VERSION ""

NS_ :

BS_:

BU_:

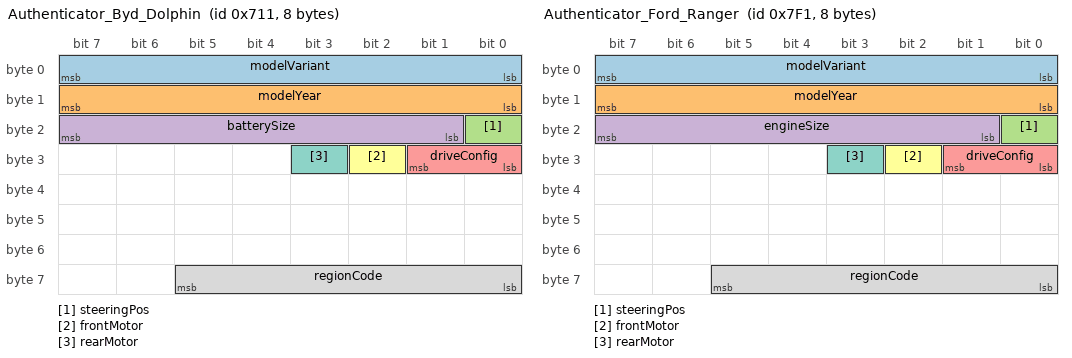
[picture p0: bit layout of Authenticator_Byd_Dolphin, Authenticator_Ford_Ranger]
BO_ 1809 Authenticator_Byd_Dolphin: 8 Vector__XXX
 SG_ modelVariant : 0|8@1+ (1,0) [0|255] "" Vector__XXX
 SG_ modelYear : 8|8@1+ (1,2020) [2020|2275] "year" Vector__XXX
 SG_ steeringPos : 16|1@1+ (1,0) [0|1] "" Vector__XXX
 SG_ batterySize : 17|7@1+ (1,0) [0|127] "kWh" Vector__XXX
 SG_ driveConfig : 24|2@1+ (1,0) [0|3] "" Vector__XXX
 SG_ frontMotor : 26|1@1+ (1,0) [0|1] "" Vector__XXX
 SG_ rearMotor : 27|1@1+ (1,0) [0|1] "" Vector__XXX
 SG_ regionCode : 56|6@1+ (1,0) [0|63] "" Vector__XXX

BO_ 2033 Authenticator_Ford_Ranger: 8 Vector__XXX
 SG_ modelVariant : 0|8@1+ (1,0) [0|255] "" Vector__XXX
 SG_ modelYear : 8|8@1+ (1,2020) [2020|2275] "year" Vector__XXX
 SG_ steeringPos : 16|1@1+ (1,0) [0|1] "" Vector__XXX
 SG_ engineSize : 17|7@1+ (0.1,0) [0|12.7] "L" Vector__XXX
 SG_ driveConfig : 24|2@1+ (1,0) [0|3] "" Vector__XXX
 SG_ frontMotor : 26|1@1+ (1,0) [0|1] "" Vector__XXX
 SG_ rearMotor : 27|1@1+ (1,0) [0|1] "" Vector__XXX
 SG_ regionCode : 56|6@1+ (1,0) [0|63] "" Vector__XXX

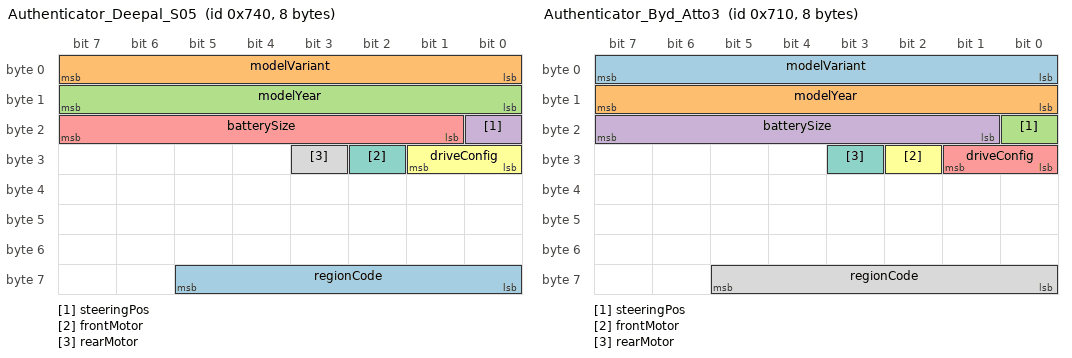
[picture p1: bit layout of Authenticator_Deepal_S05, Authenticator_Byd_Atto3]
BO_ 1856 Authenticator_Deepal_S05: 8 Vector__XXX
 SG_ regionCode : 56|6@1+ (1,0) [0|63] "" Vector__XXX
 SG_ modelVariant : 0|8@1+ (1,0) [0|255] "" Vector__XXX
 SG_ modelYear : 8|8@1+ (1,2020) [2020|2275] "year" Vector__XXX
 SG_ steeringPos : 16|1@1+ (1,0) [0|1] "" Vector__XXX
 SG_ batterySize : 17|7@1+ (1,0) [0|127] "kWh" Vector__XXX
 SG_ driveConfig : 24|2@1+ (1,0) [0|3] "" Vector__XXX
 SG_ frontMotor : 26|1@1+ (1,0) [0|1] "" Vector__XXX
 SG_ rearMotor : 27|1@1+ (1,0) [0|1] "" Vector__XXX

BO_ 1808 Authenticator_Byd_Atto3: 8 Vector__XXX
 SG_ modelVariant : 0|8@1+ (1,0) [0|255] "" Vector__XXX
 SG_ modelYear : 8|8@1+ (1,2020) [2020|2275] "year" Vector__XXX
 SG_ steeringPos : 16|1@1+ (1,0) [0|1] "" Vector__XXX
 SG_ batterySize : 17|7@1+ (1,0) [0|127] "kWh" Vector__XXX
 SG_ driveConfig : 24|2@1+ (1,0) [0|3] "" Vector__XXX
 SG_ frontMotor : 26|1@1+ (1,0) [0|1] "" Vector__XXX
 SG_ rearMotor : 27|1@1+ (1,0) [0|1] "" Vector__XXX
 SG_ regionCode : 56|6@1+ (1,0) [0|63] "" Vector__XXX

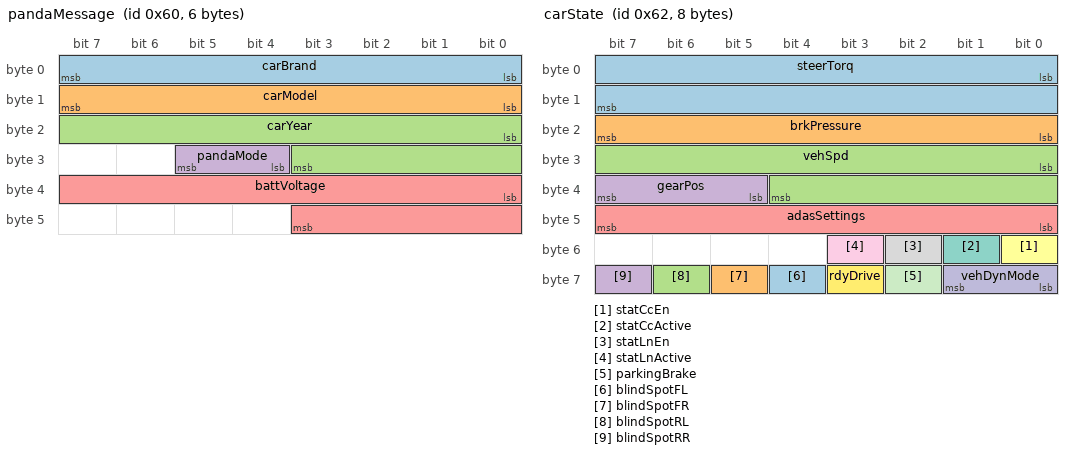
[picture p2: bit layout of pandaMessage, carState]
BO_ 96 pandaMessage: 6 Vector__XXX
 SG_ carBrand : 0|8@1+ (1,0) [0|255] "" Vector__XXX
 SG_ carModel : 8|8@1+ (1,0) [0|255] "" Vector__XXX
 SG_ carYear : 16|12@1+ (1,0) [0|4095] "" Vector__XXX
 SG_ pandaMode : 28|2@1+ (1,0) [0|3] "" Vector__XXX
 SG_ battVoltage : 32|12@1+ (0.01,0) [0|40.95] "V" Vector__XXX

BO_ 97 userCommand: 8 Vector__XXX
 SG_ brkPedal : 0|8@1+ (0.4,0) [0|102] "%" Vector__XXX
 SG_ accPedal : 8|8@1+ (0.4,0) [0|102] "%" Vector__XXX
 SG_ steerAngle : 16|16@1+ (0.1,0) [-780|780] "deg" Vector__XXX
 SG_ yawRate : 32|14@1+ (0.01,-81.91) [-81.91|81.91] "deg/s" Vector__XXX
 SG_ btnCcEn : 46|1@1+ (1,0) [0|1] "" Vector__XXX
 SG_ btnLaneEn : 47|1@1+ (1,0) [0|1] "" Vector__XXX
 SG_ btnGeneric : 48|1@1+ (1,0) [0|1] "" Vector__XXX
 SG_ btnCcSet : 49|1@1+ (1,0) [0|1] "" Vector__XXX
 SG_ btnCcCancel : 50|1@1+ (1,0) [0|1] "" Vector__XXX
 SG_ btnCcResume : 51|1@1+ (1,0) [0|1] "" Vector__XXX
 SG_ btnSpdUp : 52|1@1+ (1,0) [0|1] "" Vector__XXX
 SG_ btnSpdDn : 53|1@1+ (1,0) [0|1] "" Vector__XXX
 SG_ btnDistNr : 54|1@1+ (1,0) [0|1] "" Vector__XXX
 SG_ btnDistFar : 55|1@1+ (1,0) [0|1] "" Vector__XXX
 SG_ btnHazard : 56|1@1+ (1,0) [0|1] "" Vector__XXX
 SG_ btnBlinkL : 57|1@1+ (1,0) [0|1] "" Vector__XXX
 SG_ btnBlinkR : 58|1@1+ (1,0) [0|1] "" Vector__XXX
 SG_ actPedalPressed : 59|1@1+ (1,0) [0|1] "" Vector__XXX
 SG_ actBrakePressed : 60|1@1+ (1,0) [0|1] "" Vector__XXX
 SG_ actSteerPressed : 61|1@1+ (1,0) [0|1] "" Vector__XXX

BO_ 98 carState: 8 Vector__XXX
 SG_ steerTorq : 0|16@1+ (0.1,-3276.8) [-3276.8|3276.7] "Nm" Vector__XXX
 SG_ brkPressure : 16|8@1+ (0.1,0) [0|25.5] "bar" Vector__XXX
 SG_ vehSpd : 24|13@1+ (0.05625,0) [0|360] "km/h" Vector__XXX
 SG_ gearPos : 37|3@1+ (1,0) [0|7] "" Vector__XXX
 SG_ adasSettings : 40|8@1+ (1,0) [0|255] "" Vector__XXX
 SG_ statCcEn : 48|1@1+ (1,0) [0|1] "" Vector__XXX
 SG_ statCcActive : 49|1@1+ (1,0) [0|1] "" Vector__XXX
 SG_ statLnEn : 50|1@1+ (1,0) [0|1] "" Vector__XXX
 SG_ statLnActive : 51|1@1+ (1,0) [0|1] "" Vector__XXX
 SG_ vehDynMode : 56|2@1+ (1,0) [0|3] "" Vector__XXX
 SG_ parkingBrake : 58|1@1+ (1,0) [0|1] "" Vector__XXX
 SG_ rdyDrive : 59|1@1+ (1,0) [0|1] "" Vector__XXX
 SG_ blindSpotFL : 60|1@1+ (1,0) [0|1] "" Vector__XXX
 SG_ blindSpotFR : 61|1@1+ (1,0) [0|1] "" Vector__XXX
 SG_ blindSpotRL : 62|1@1+ (1,0) [0|1] "" Vector__XXX
 SG_ blindSpotRR : 63|1@1+ (1,0) [0|1] "" Vector__XXX

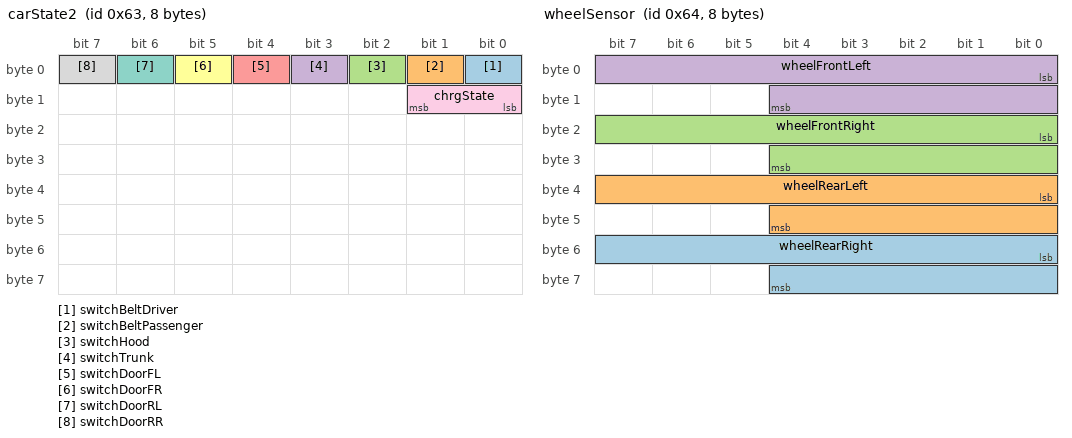
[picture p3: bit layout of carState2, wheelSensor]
BO_ 99 carState2: 8 Vector__XXX
 SG_ switchBeltDriver : 0|1@1+ (1,0) [0|1] "" Vector__XXX
 SG_ switchBeltPassenger : 1|1@1+ (1,0) [0|1] "" Vector__XXX
 SG_ switchHood : 2|1@1+ (1,0) [0|1] "" Vector__XXX
 SG_ switchTrunk : 3|1@1+ (1,0) [0|1] "" Vector__XXX
 SG_ switchDoorFL : 4|1@1+ (1,0) [0|1] "" Vector__XXX
 SG_ switchDoorFR : 5|1@1+ (1,0) [0|1] "" Vector__XXX
 SG_ switchDoorRL : 6|1@1+ (1,0) [0|1] "" Vector__XXX
 SG_ switchDoorRR : 7|1@1+ (1,0) [0|1] "" Vector__XXX
 SG_ chrgState : 8|2@1+ (1,0) [0|3] "" Vector__XXX

BO_ 100 wheelSensor: 8 Vector__XXX
 SG_ wheelRearRight : 48|13@1+ (0.05625,0) [0|360] "km/h" Vector__XXX
 SG_ wheelRearLeft : 32|13@1+ (0.05625,0) [0|360] "km/h" Vector__XXX
 SG_ wheelFrontRight : 16|13@1+ (0.05625,0) [0|360] "km/h" Vector__XXX
 SG_ wheelFrontLeft : 0|13@1+ (0.05625,0) [0|360] "km/h" Vector__XXX

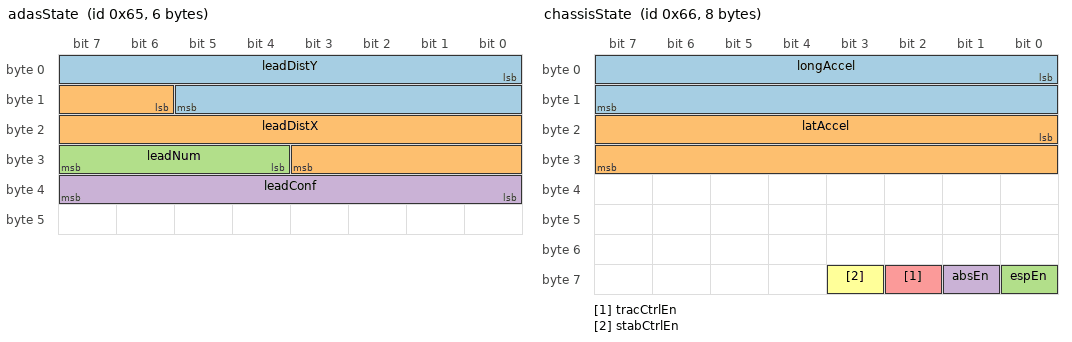
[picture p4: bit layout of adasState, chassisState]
BO_ 101 adasState: 6 Vector__XXX
 SG_ leadDistY : 0|14@1+ (0.04,0) [0|655.32] "m" Vector__XXX
 SG_ leadDistX : 14|14@1+ (0.04,0) [0|655.32] "m" Vector__XXX
 SG_ leadNum : 28|4@1+ (1,0) [0|3] "" Vector__XXX
 SG_ leadConf : 32|8@1+ (0.4,0) [0|102] "%" Vector__XXX

BO_ 102 chassisState: 8 Vector__XXX
 SG_ longAccel : 0|16@1+ (0.001,-32.768) [-32.768|32.767] "m/s2" Vector__XXX
 SG_ latAccel : 16|16@1+ (0.001,-32.768) [-32.768|32.767] "m/s2" Vector__XXX
 SG_ espEn : 56|1@1+ (1,0) [0|1] "" Vector__XXX
 SG_ absEn : 57|1@1+ (1,0) [0|1] "" Vector__XXX
 SG_ tracCtrlEn : 58|1@1+ (1,0) [0|1] "" Vector__XXX
 SG_ stabCtrlEn : 59|1@1+ (1,0) [0|1] "" Vector__XXX

BO_ 103 drivetrainState: 8 Vector__XXX
 SG_ gearRatio : 0|6@1+ (0.1,0) [0|6.3] "" Vector__XXX

BO_ 104 powertrainState: 8 Vector__XXX
 SG_ engRun : 0|1@1+ (1,0) [0|1] "" Vector__XXX
 SG_ pwrFault : 4|4@1+ (1,0) [0|15] "" Vector__XXX
 SG_ coolTemp : 8|8@1+ (1,-40) [-40|215] "C" Vector__XXX
 SG_ fuelLvl : 16|8@1+ (0.4,0) [0|102] "%" Vector__XXX
 SG_ battTemp : 24|8@1+ (1,-40) [-40|215] "C" Vector__XXX
 SG_ battLvl : 32|8@1+ (0.4,0) [0|102] "%" Vector__XXX
 SG_ engRPM : 48|16@1+ (0.25,0) [0|16383.75] "rpm" Vector__XXX
 SG_ engType : 62|2@1+ (1,0) [0|3] "" Vector__XXX

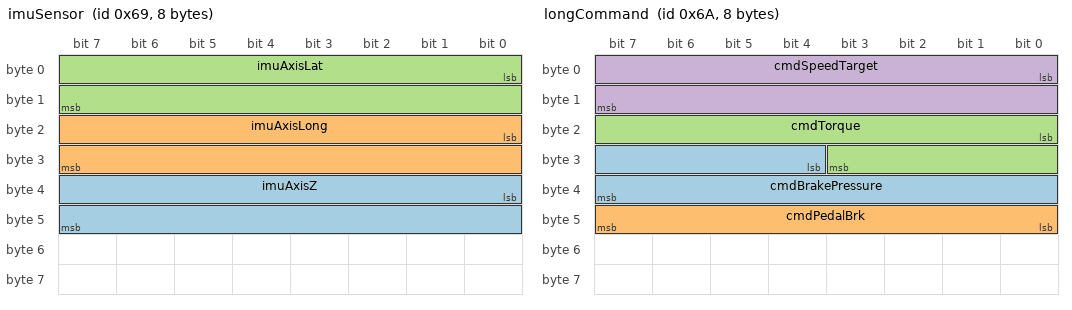
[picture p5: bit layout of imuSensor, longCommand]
BO_ 105 imuSensor: 8 Vector__XXX
 SG_ imuAxisZ : 32|16@1+ (0.001,-32.768) [-32.768|32.767] "m/s2" Vector__XXX
 SG_ imuAxisLong : 16|16@1+ (0.001,-32.768) [-32.768|32.767] "m/s2" Vector__XXX
 SG_ imuAxisLat : 0|16@1+ (0.001,-32.768) [-32.768|32.767] "m/s2" Vector__XXX

BO_ 106 longCommand: 8 Vector__XXX
 SG_ cmdBrakePressure : 28|12@1+ (0.015625,0) [0|1023.984375] "bar" Vector__XXX
 SG_ cmdPedalBrk : 40|8@1+ (0.4,0) [0|102] "%" Vector__XXX
 SG_ cmdTorque : 16|12@1+ (5,-5000) [-5000|15475] "NM" Vector__XXX
 SG_ cmdSpeedTarget : 0|16@1+ (0.01,0) [0|655.35] "km/h" Vector__XXX

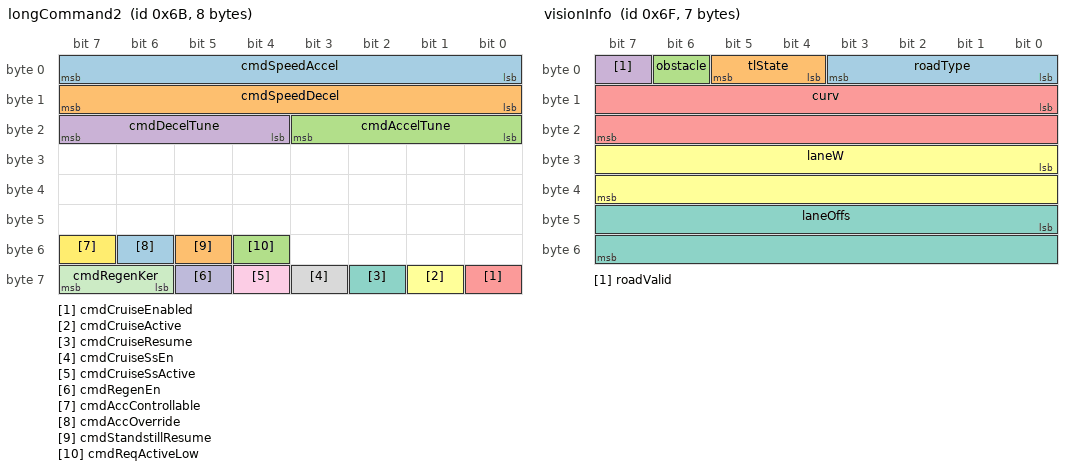
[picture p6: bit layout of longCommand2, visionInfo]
BO_ 107 longCommand2: 8 Vector__XXX
 SG_ cmdSpeedAccel : 0|8@1+ (0.05,-10) [-10|2.75] "m/s2" Vector__XXX
 SG_ cmdSpeedDecel : 8|8@1+ (0.05,-10) [-10|2.75] "m/s2" Vector__XXX
 SG_ cmdAccelTune : 16|4@1+ (1,0) [0|15] "" Vector__XXX
 SG_ cmdDecelTune : 20|4@1+ (1,0) [0|15] "" Vector__XXX
 SG_ cmdCruiseEnabled : 56|1@1+ (1,0) [0|1] "" Vector__XXX
 SG_ cmdCruiseActive : 57|1@1+ (1,0) [0|1] "" Vector__XXX
 SG_ cmdCruiseResume : 58|1@1+ (1,0) [0|1] "" Vector__XXX
 SG_ cmdCruiseSsEn : 59|1@1+ (1,0) [0|1] "" Vector__XXX
 SG_ cmdCruiseSsActive : 60|1@1+ (1,0) [0|1] "" Vector__XXX
 SG_ cmdRegenEn : 61|1@1+ (1,0) [0|1] "" Vector__XXX
 SG_ cmdRegenKer : 62|2@1+ (1,0) [0|1] "" Vector__XXX
 SG_ cmdAccControllable : 55|1@1+ (1,0) [0|1] "" Vector__XXX
 SG_ cmdAccOverride : 54|1@1+ (1,0) [0|1] "" Vector__XXX
 SG_ cmdStandstillResume : 53|1@1+ (1,0) [0|1] "" Vector__XXX
 SG_ cmdReqActiveLow : 52|1@1+ (1,0) [0|1] "" Vector__XXX

BO_ 108 latCommand: 8 Vector__XXX
 SG_ cmdSteerAngle : 0|16@1+ (0.1,-3276.8) [-3276.8|3276.7] "deg" Vector__XXX
 SG_ cmdSteerTorque : 16|16@1+ (0.01,-327.68) [-327.68|327.67] "Nm" Vector__XXX
 SG_ cmdSteerMode : 56|1@1+ (1,0) [0|1] "" Vector__XXX
 SG_ cmdSteerEnable : 57|1@1+ (1,0) [0|1] "" Vector__XXX
 SG_ cmdLaneActive : 58|1@1+ (1,0) [0|1] "" Vector__XXX
 SG_ cmdSteerAlert : 59|2@1+ (1,0) [0|3] "" Vector__XXX
 SG_ cmdSteerShake : 60|2@1+ (1,0) [0|3] "" Vector__XXX
 SG_ cmdLaneEnable : 62|1@1+ (1,0) [0|1] "" Vector__XXX
 SG_ cmdLaneAlert : 63|1@1+ (1,0) [0|1] "" Vector__XXX

BO_ 109 latCommand2: 8 Vector__XXX

BO_ 110 dispCommand: 8 Vector__XXX
 SG_ cmdDispCcEn : 0|1@1+ (1,0) [0|1] "" Vector__XXX
 SG_ cmdDispCcActive : 1|1@1+ (1,0) [0|1] "" Vector__XXX
 SG_ cmdDispLnEn : 2|1@1+ (1,0) [0|1] "" Vector__XXX
 SG_ cmdDispLnActive : 3|1@1+ (1,0) [0|1] "" Vector__XXX
 SG_ cmdDispSoundAlert : 4|1@1+ (1,0) [0|1] "" Vector__XXX
 SG_ cmdDispLeadC : 5|1@1+ (1,0) [0|1] "" Vector__XXX
 SG_ cmdDispLeadR : 6|1@1+ (1,0) [0|1] "" Vector__XXX
 SG_ cmdDispLeadL : 7|1@1+ (1,0) [0|1] "" Vector__XXX
 SG_ cmdDispDepartLeft : 8|1@1+ (1,0) [0|1] "" Vector__XXX
 SG_ cmdDispDepartRight : 9|1@1+ (1,0) [0|1] "" Vector__XXX
 SG_ cmdDispLane1 : 10|1@1+ (1,0) [0|1] "" Vector__XXX
 SG_ cmdDispLane2 : 11|1@1+ (1,0) [0|1] "" Vector__XXX
 SG_ cmdDispLane3 : 12|1@1+ (1,0) [0|1] "" Vector__XXX
 SG_ cmdDispLane4 : 13|1@1+ (1,0) [0|1] "" Vector__XXX
 SG_ cmdDispRoadEdgeLeft : 14|1@1+ (1,0) [0|1] "" Vector__XXX
 SG_ cmdDispRoadEdgeRight : 15|1@1+ (1,0) [0|1] "" Vector__XXX
 SG_ cmdDispFollowDistance : 16|2@1+ (1,0) [0|7] "" Vector__XXX
 SG_ cmdDispSpeed : 32|16@1+ (0.01,0) [0|655.35] "km/h" Vector__XXX
 SG_ cmdDispPassThrough : 48|16@1+ (1,0) [0|65535] "" Vector__XXX

BO_ 111 visionInfo: 7 Vector__XXX
 SG_ roadType : 0|4@1+ (1,0) [0|15] "" Vector__XXX
 SG_ tlState : 4|2@1+ (1,0) [0|3] "" Vector__XXX
 SG_ obstacle : 6|1@1+ (1,0) [0|1] "" Vector__XXX
 SG_ roadValid : 7|1@1+ (1,0) [0|1] "" Vector__XXX
 SG_ curv : 8|16@1+ (0.0001,-3.2768) [-3.2768|3.2767] "1/m" Vector__XXX
 SG_ laneW : 24|16@1+ (0.01,0) [0|655.35] "m" Vector__XXX
 SG_ laneOffs : 40|16@1+ (0.01,-327.68) [-327.68|327.67] "m" Vector__XXX

BA_DEF_  "BusType" STRING ;
BA_DEF_  "DBName" STRING ;
BA_DEF_ BO_  "GenMsgCycleTime" INT 0 3600000;
BA_DEF_ SG_  "GenSigStartValue" FLOAT 0 0;
BA_DEF_DEF_  "BusType" "CAN";
BA_DEF_DEF_  "DBName" "BROWNPANDA";
BA_DEF_DEF_  "GenMsgCycleTime" 100;
BA_DEF_DEF_  "GenSigStartValue" 0;
BA_ "GenMsgCycleTime" BO_ 97 10;
BA_ "GenMsgCycleTime" BO_ 98 10;
BA_ "GenMsgCycleTime" BO_ 99 20;
BA_ "GenMsgCycleTime" BO_ 100 50;
BA_ "GenMsgCycleTime" BO_ 102 50;
BA_ "GenMsgCycleTime" BO_ 103 50;
BA_ "GenMsgCycleTime" BO_ 104 20;
BA_ "GenMsgCycleTime" BO_ 105 10;
BA_ "GenMsgCycleTime" BO_ 106 10;
BA_ "GenMsgCycleTime" BO_ 107 20;
BA_ "GenMsgCycleTime" BO_ 108 10;
BA_ "GenMsgCycleTime" BO_ 109 20;
BA_ "GenMsgCycleTime" BO_ 110 20;
BA_ "GenMsgCycleTime" BO_ 111 20;
BA_ "GenSigStartValue" SG_ 106 cmdTorque 1000;
BA_ "GenSigStartValue" SG_ 107 cmdSpeedAccel -455.36;
BA_ "GenSigStartValue" SG_ 107 cmdSpeedDecel -455.36;
VAL_ 1809 modelVariant 1 "DOLPHIN_ACTIVE" 2 "DOLPHIN_BOOST" 3 "DOLPHIN_PREMIUM" 4 "DOLPHIN_KNIGHT" 5 "DOLPHIN_FASHION" ;
VAL_ 1809 steeringPos 0 "LHD" 1 "RHD" ;
VAL_ 1809 driveConfig 0 "FWD" 1 "RWD" 2 "AWD" 3 "4WD" ;
VAL_ 1809 frontMotor 0 "NO_MOTOR" 1 "MOTOR_PRESENT" ;
VAL_ 1809 rearMotor 0 "NO_MOTOR" 1 "MOTOR_PRESENT" ;
VAL_ 1809 regionCode 1 "CHINA" 2 "EUROPE" 3 "AUSTRALIA" 4 "THAILAND" 5 "BRAZIL" 6 "MIDDLE_EAST" 7 "SINGAPORE" 8 "JAPAN" 9 "NEW_ZEALAND" 10 "SOUTH_AFRICA" ;
VAL_ 2033 modelVariant 1 "RANGER_XL" 2 "RANGER_XLT" 3 "RANGER_LARIAT" 4 "RANGER_RAPTOR" 5 "RANGER_WILDTRAK" ;
VAL_ 2033 steeringPos 0 "LHD" 1 "RHD" ;
VAL_ 2033 driveConfig 0 "FWD" 1 "RWD" 2 "AWD" 3 "4WD" ;
VAL_ 2033 frontMotor 0 "NO_MOTOR" 1 "ENGINE_PRESENT" ;
VAL_ 2033 rearMotor 0 "NO_MOTOR" 1 "DIFFERENTIAL_PRESENT" ;
VAL_ 2033 regionCode 1 "USA" 2 "EUROPE" 3 "AUSTRALIA" 4 "THAILAND" 5 "ARGENTINA" 6 "SOUTH_AFRICA" 7 "CANADA" 8 "MEXICO" 9 "BRAZIL" 10 "PHILIPPINES" ;
VAL_ 1856 regionCode 1 "CHINA" 2 "EUROPE" 3 "AUSTRALIA" 4 "THAILAND" 5 "BRAZIL" 6 "MIDDLE_EAST" 7 "SINGAPORE" 8 "JAPAN" 9 "NEW_ZEALAND" 10 "SOUTH_AFRICA" ;
VAL_ 1856 modelVariant 1 "S05_COMFORT" 2 "S05_LUXURY" 3 "S05_PERFORMANCE" 4 "S05_ULTIMATE" 5 "S05_CHAMPION" ;
VAL_ 1856 steeringPos 0 "LHD" 1 "RHD" ;
VAL_ 1856 driveConfig 0 "FWD" 1 "RWD" 2 "AWD" 3 "4WD" ;
VAL_ 1856 frontMotor 0 "NO_MOTOR" 1 "MOTOR_PRESENT" ;
VAL_ 1856 rearMotor 0 "NO_MOTOR" 1 "MOTOR_PRESENT" ;
VAL_ 1808 modelVariant 1 "ATTO3_STANDARD" 2 "ATTO3_EXTENDED" 3 "ATTO3_PREMIUM" 4 "ATTO3_COMFORT" 5 "ATTO3_DESIGN" ;
VAL_ 1808 steeringPos 0 "LHD" 1 "RHD" ;
VAL_ 1808 driveConfig 0 "FWD" 1 "RWD" 2 "AWD" 3 "4WD" ;
VAL_ 1808 frontMotor 0 "NO_MOTOR" 1 "MOTOR_PRESENT" ;
VAL_ 1808 rearMotor 0 "NO_MOTOR" 1 "MOTOR_PRESENT" ;
VAL_ 1808 regionCode 1 "CHINA" 2 "EUROPE" 3 "AUSTRALIA" 4 "THAILAND" 5 "BRAZIL" 6 "MIDDLE_EAST" 7 "SINGAPORE" 8 "JAPAN" 9 "NEW_ZEALAND" 10 "SOUTH_AFRICA" ;
VAL_ 96 carBrand 0 "UNKNOWN" 1 "BYD" 2 "CHANGAN" 3 "GWM" 4 "GAC" 5 "SAIC" 6 "CHERY" 7 "ZEEKR" 8 "BAIC" 9 "TOYOTA" 10 "ISUZU" 11 "HONDA" 12 "MITSUBISHI" 13 "MERCEDES" 14 "BMW" 15 "PORSCHE" ;
VAL_ 96 carModel 0 "UNKNOWN" 1 "BYD_SEAL" 2 "BYD_HAN" 3 "BYD_TANG" 4 "CHANGAN_UNI" 5 "GWM_ORA" 6 "GAC_AION" 7 "SAIC_MG" 8 "CHERY_TIGGO" 9 "ZEEKR_001" 10 "BAIC_EU" 11 "TOYOTA_CAMRY" 12 "ISUZU_DMAX" 13 "HONDA_ACCORD" 14 "MITSUBISHI_OUTLANDER" 15 "MERCEDES_C_CLASS" 16 "BMW_3_SERIES" 17 "PORSCHE_TAYCAN" ;
VAL_ 96 pandaMode 0 "OEM_MODE" 1 "INTERRUPT_MODE" 2 "OVERRIDE_MODE" 3 "DIAGNOSTIC_MODE" ;
VAL_ 97 btnCcEn 0 "NOT_PRESSED" 1 "PRESSED" ;
VAL_ 97 btnLaneEn 0 "NOT_PRESSED" 1 "PRESSED" ;
VAL_ 97 btnGeneric 0 "NOT_PRESSED" 1 "PRESSED" ;
VAL_ 97 btnCcSet 0 "NOT_PRESSED" 1 "PRESSED" ;
VAL_ 97 btnCcCancel 0 "NOT_PRESSED" 1 "PRESSED" ;
VAL_ 97 btnCcResume 0 "NOT_PRESSED" 1 "PRESSED" ;
VAL_ 97 btnSpdUp 0 "NOT_PRESSED" 1 "PRESSED" ;
VAL_ 97 btnSpdDn 0 "NOT_PRESSED" 1 "PRESSED" ;
VAL_ 97 btnDistNr 0 "NOT_PRESSED" 1 "PRESSED" ;
VAL_ 97 btnDistFar 0 "NOT_PRESSED" 1 "PRESSED" ;
VAL_ 97 btnHazard 0 "OFF" 1 "ON" ;
VAL_ 97 btnBlinkL 0 "OFF" 1 "ON" ;
VAL_ 97 btnBlinkR 0 "OFF" 1 "ON" ;
VAL_ 97 actPedalPressed 0 "NOT_PRESSED" 1 "PRESSED" ;
VAL_ 97 actBrakePressed 0 "NOT_PRESSED" 1 "PRESSED" ;
VAL_ 97 actSteerPressed 0 "NOT_PRESSED" 1 "PRESSED" ;
VAL_ 98 gearPos 0 "PARK" 1 "REVERSE" 2 "NEUTRAL" 3 "DRIVE" 4 "SPORT" 5 "LOW" 6 "MANUAL" 7 "RESERVED" ;
VAL_ 98 statCcEn 0 "DISABLED" 1 "ENABLED" ;
VAL_ 98 statCcActive 0 "INACTIVE" 1 "ACTIVE" ;
VAL_ 98 statLnEn 0 "DISABLED" 1 "ENABLED" ;
VAL_ 98 statLnActive 0 "INACTIVE" 1 "ACTIVE" ;
VAL_ 98 vehDynMode 0 "NORMAL" 1 "ECO" 2 "SPORT" 3 "OTHERS" ;
VAL_ 98 parkingBrake 0 "RELEASED" 1 "ENGAGED" ;
VAL_ 98 rdyDrive 0 "NOT_READY" 1 "READY" ;
VAL_ 98 blindSpotFL 0 "NO_VEHICLE" 1 "VEHICLE_DETECTED" ;
VAL_ 98 blindSpotFR 0 "NO_VEHICLE" 1 "VEHICLE_DETECTED" ;
VAL_ 98 blindSpotRL 0 "NO_VEHICLE" 1 "VEHICLE_DETECTED" ;
VAL_ 98 blindSpotRR 0 "NO_VEHICLE" 1 "VEHICLE_DETECTED" ;
VAL_ 99 switchBeltDriver 0 "UNBUCKLED" 1 "BUCKLED" ;
VAL_ 99 switchBeltPassenger 0 "UNBUCKLED" 1 "BUCKLED" ;
VAL_ 99 switchHood 0 "CLOSED" 1 "OPEN" ;
VAL_ 99 switchTrunk 0 "CLOSED" 1 "OPEN" ;
VAL_ 99 switchDoorFL 0 "CLOSED" 1 "OPEN" ;
VAL_ 99 switchDoorFR 0 "CLOSED" 1 "OPEN" ;
VAL_ 99 switchDoorRL 0 "CLOSED" 1 "OPEN" ;
VAL_ 99 switchDoorRR 0 "CLOSED" 1 "OPEN" ;
VAL_ 99 chrgState 0 "NOT_CHARGING" 1 "AC_CHARGING" 2 "DC_CHARGING" 3 "WIRELESS_CHARGING" ;
VAL_ 101 leadNum 0 "NO_LEAD" 1 "LEAD_1" 2 "LEAD_2" 3 "MULTIPLE_LEADS" ;
VAL_ 102 espEn 0 "DISABLED" 1 "ENABLED" ;
VAL_ 102 absEn 0 "DISABLED" 1 "ENABLED" ;
VAL_ 102 tracCtrlEn 0 "DISABLED" 1 "ENABLED" ;
VAL_ 102 stabCtrlEn 0 "DISABLED" 1 "ENABLED" ;
VAL_ 104 engRun 0 "STOPPED" 1 "RUNNING" ;
VAL_ 104 pwrFault 0 "NO_FAULT" 1 "OVERHEAT" 2 "UNDERVOLTAGE" 3 "OVERVOLTAGE" 4 "OVERCURRENT" 5 "SENSOR_FAULT" 6 "COMMUNICATION_FAULT" 7 "SYSTEM_FAULT" 15 "UNKNOWN_FAULT" ;
VAL_ 104 engType 0 "ICE" 1 "HEV" 2 "BEV" 3 "FCEV" ;
VAL_ 107 cmdAccelTune 0 "MIN" 15 "MAX" ;
VAL_ 107 cmdDecelTune 0 "MIN" 15 "MAX" ;
VAL_ 107 cmdCruiseEnabled 0 "DISABLED" 1 "ENABLED" ;
VAL_ 107 cmdCruiseActive 0 "INACTIVE" 1 "ACTIVE" ;
VAL_ 107 cmdCruiseResume 0 "NOT_PRESSED" 1 "PRESSED" ;
VAL_ 107 cmdCruiseSsEn 0 "MOVING" 1 "STANDSTILL" ;
VAL_ 107 cmdCruiseSsActive 0 "MOVING" 1 "STANDSTILL" ;
VAL_ 107 cmdRegenEn 0 "DISABLED" 1 "ENABLED" ;
VAL_ 107 cmdRegenKer 0 "DISABLED" 1 "ENABLED" ;
VAL_ 108 cmdSteerMode 0 "MANUAL" 1 "ASSIST" ;
VAL_ 108 cmdSteerEnable 0 "DISABLED" 1 "ENABLED" ;
VAL_ 108 cmdLaneActive 0 "INACTIVE" 1 "ACTIVE" ;
VAL_ 108 cmdSteerAlert 0 "NO_ALERT" 1 "ATTENTION" 2 "WARNING" 3 "CRITICAL" ;
VAL_ 108 cmdSteerShake 0 "NO_SHAKE" 1 "SHAKE_ACTIVE" 2 "SHAKE_WARNING" 3 "SHAKE_CRITICAL" ;
VAL_ 108 cmdLaneEnable 0 "DISABLED" 1 "ENABLED" ;
VAL_ 108 cmdLaneAlert 0 "NO_ALERT" 1 "ALERT_ACTIVE" ;
VAL_ 110 cmdDispCcEn 0 "CRUISE_DISABLED" 1 "CRUISE_ENABLED" ;
VAL_ 110 cmdDispCcActive 0 "CRUISE_DISABLED" 1 "CRUISE_ENABLED" ;
VAL_ 110 cmdDispLnEn 0 "LANE_ASSIST_OFF" 1 "LANE_ASSIST_ON" ;
VAL_ 110 cmdDispLnActive 0 "CRUISE_DISABLED" 1 "CRUISE_ENABLED" ;
VAL_ 110 cmdDispSoundAlert 0 "NO_ALERT" 1 "ALERT_ACTIVE" ;
VAL_ 110 cmdDispLeadC 0 "NO_LEAD" 1 "LEAD_DETECTED" ;
VAL_ 110 cmdDispLeadR 0 "NO_LEAD" 1 "LEAD_DETECTED" ;
VAL_ 110 cmdDispLeadL 0 "NO_LEAD" 1 "LEAD_DETECTED" ;
VAL_ 110 cmdDispDepartLeft 0 "NO_DEPARTURE" 1 "DEPARTING_LEFT" ;
VAL_ 110 cmdDispDepartRight 0 "NO_DEPARTURE" 1 "DEPARTING_RIGHT" ;
VAL_ 110 cmdDispLane1 0 "NO_LANE" 1 "SOLID_LINE" 2 "DASHED_LINE" ;
VAL_ 110 cmdDispLane2 0 "NO_LANE" 1 "SOLID_LINE" 2 "DASHED_LINE" ;
VAL_ 110 cmdDispLane3 0 "NO_LANE" 1 "SOLID_LINE" 2 "DASHED_LINE" ;
VAL_ 110 cmdDispLane4 0 "NO_LANE" 1 "SOLID_LINE" 2 "DASHED_LINE" ;
VAL_ 110 cmdDispRoadEdgeLeft 0 "NO_LANE" 1 "SOLID_LINE" 2 "DASHED_LINE" ;
VAL_ 110 cmdDispRoadEdgeRight 0 "NO_LANE" 1 "SOLID_LINE" 2 "DASHED_LINE" ;
VAL_ 110 cmdDispFollowDistance 0 "VERY_CLOSE" 1 "CLOSE" 2 "MEDIUM" 3 "FAR" 4 "VERY_FAR" 5 "EXTRA_FAR" 6 "MAXIMUM" 7 "AUTO" ;
VAL_ 111 roadType 0 "UNKNOWN" 1 "HIGHWAY" 2 "CITY_STREET" 3 "PARKING_LOT" 4 "TUNNEL" 5 "BRIDGE" 6 "ROUNDABOUT" 7 "INTERSECTION" 8 "CONSTRUCTION" 9 "SCHOOL_ZONE" 10 "TOLL_BOOTH" 11 "SERVICE_AREA" 12 "RAMP" 13 "PRIVATE_ROAD" 14 "EMERGENCY_LANE" 15 "INVALID" ;
VAL_ 111 tlState 0 "UNKNOWN" 1 "GREEN" 2 "YELLOW" 3 "RED" ;
VAL_ 111 obstacle 0 "NO_OBSTACLE" 1 "OBSTACLE_DETECTED" ;
VAL_ 111 roadValid 0 "INVALID" 1 "VALID" ;
